LIN_description_file;
LIN_protocol_version = "2.0";
LIN_language_version = "2.0";
LIN_speed = 19.2 kbps;

Nodes {
  Master: bcm, 5.0 ms, 0.1 ms ;
  Slaves: scs, wbp, wpa,lsn;
}

Signals {
    Left_Turn_Btn: 1, 0, lsn, bcm ;
    Right_Turn_Btn: 1, 0, lsn, bcm ;
    Hazard_Btn: 1, 0, lsn, bcm ;
    Low_Beam_Btn: 1, 0, lsn, bcm ;
    High_Beam_Btn: 1, 0, lsn, bcm ;
    Parking_Btn: 1, 0, lsn, bcm ;
    Brake_Btn: 1, 0, lsn, bcm ;
    Reverse_Btn: 1, 0, lsn, bcm ;
    Front_Fog_Btn: 1, 0, lsn, bcm ;
    Rear_Fog_Btn: 1, 0, lsn, bcm ;
    Flash_Btn: 1, 0, lsn, bcm ;
    PWF_Bit0: 1, 0, lsn, bcm ;
    PWF_Bit1: 1, 0, lsn, bcm ;
    Door_FL_Status: 1, 0, lsn, bcm ;
    Door_FR_Status: 1, 0, lsn, bcm ;
    Door_RL_Status: 1, 0, lsn, bcm ;
    Door_RR_Status: 1, 0, lsn, bcm ;
    Window1_State: 8, 0, wbp, bcm ;
    Window2_State: 8, 0, wbp, bcm ;
    Window3_State: 8, 0, wbp, bcm ;
    Window4_State: 8, 0, wbp, bcm ;
    Child_Safety: 1, 0, wbp, bcm ;
    Door_Lock: 1, 0, wbp, bcm ;
    WBP_NodeState: 8, 1, wbp, bcm ;
    WBP_AdcHealth: 8, 0, wbp, bcm ;
    WBP_Reserved0: 8, 0, wbp, bcm ;
    WBP_Reserved1: 8, 0, wbp, bcm ;
}

Frames {
    LSN_Input_Frame : 0x14, lsn, 5 {
        Low_Beam_Btn, 38 ; /* byte 4, bit 6 */
        Left_Turn_Btn, 36 ; /* byte 4, bit 4 */
        Right_Turn_Btn, 37 ; /* byte 4, bit 5 */
        Hazard_Btn, 0 ; /* byte 0, bit 0 */
        High_Beam_Btn, 31 ; /* byte 3, bit 7 */
        Parking_Btn, 39 ; /* byte 4, bit 7 */
        Front_Fog_Btn, 35 ; /* byte 4, bit 3 */
        Rear_Fog_Btn, 34 ; /* byte 4, bit 2 */
        Brake_Btn, 30 ; /* byte 3, bit 6 */
        Reverse_Btn, 12 ; /* byte 1, bit 4 */
        Flash_Btn, 32 ; /* byte 4, bit 0 — normally 1, goes 0 when pulled */
        PWF_Bit0, 14 ; /* byte 1, bit 6 */
        PWF_Bit1, 13 ; /* byte 1, bit 5 */
        Door_FL_Status, 11 ; /* byte 1, bit 3 */
        Door_FR_Status, 9 ; /* byte 1, bit 1 */
        Door_RL_Status, 10 ; /* byte 1, bit 2 */
        Door_RR_Status, 8 ; /* byte 1, bit 0 */
    }
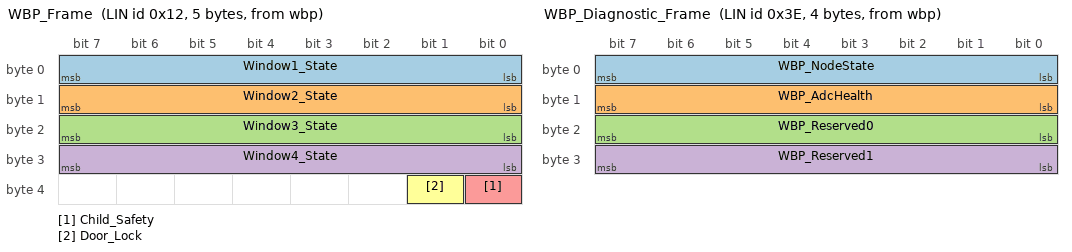
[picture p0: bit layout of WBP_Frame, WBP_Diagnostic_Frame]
    WBP_Frame : 0x12, wbp, 5 {
        Window1_State, 0 ;
        Window2_State, 8 ;
        Window3_State, 16 ;
        Window4_State, 24 ;
        Child_Safety, 32 ;
        Door_Lock, 33 ;
    }
    WBP_Diagnostic_Frame : 0x3E, wbp, 4 {
        WBP_NodeState, 0 ;
        WBP_AdcHealth, 8 ;
        WBP_Reserved0, 16 ;
        WBP_Reserved1, 24 ;

    }
}

Schedule_tables {
    Normal_Table {
        LSN_Input_Frame delay 5.0 ms ;
        event_triggered WBP_Frame delay 5.0 ms ;
    }
    Diagnostic_Table {
        MasterReq delay 10.0 ms ;
        SlaveResp delay 10.0 ms ;
        WBP_Diagnostic_Frame delay 10.0 ms ;
    }
}
